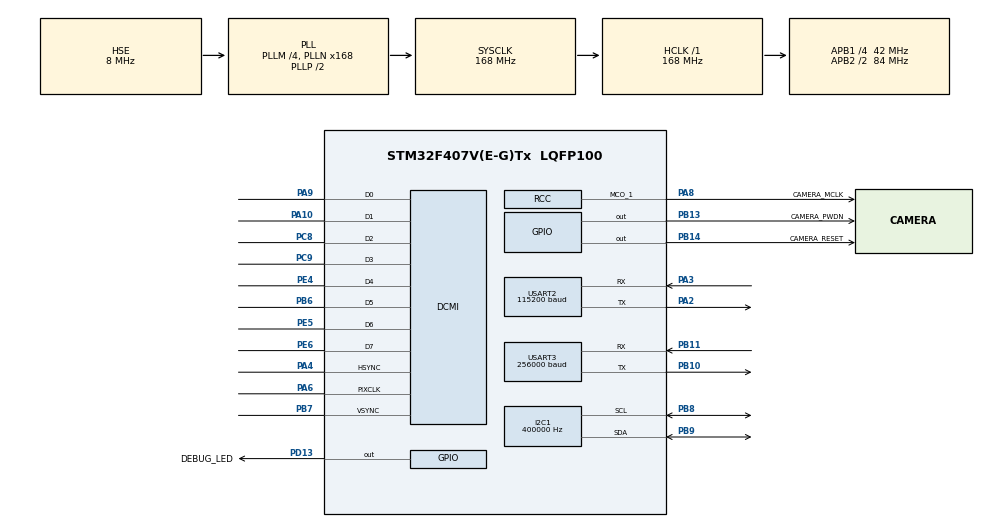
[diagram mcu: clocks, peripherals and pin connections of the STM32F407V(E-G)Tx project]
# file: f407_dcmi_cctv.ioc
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DCMI.JPEGMode=DCMI_JPEG_ENABLE
DCMI.PCKPolarity=DCMI_PCKPOLARITY_RISING
Dma.DCMI.0.Direction=DMA_PERIPH_TO_MEMORY
Dma.DCMI.0.FIFOMode=DMA_FIFOMODE_ENABLE
Dma.DCMI.0.FIFOThreshold=DMA_FIFO_THRESHOLD_FULL
Dma.DCMI.0.Instance=DMA2_Stream1
Dma.DCMI.0.MemBurst=DMA_MBURST_SINGLE
Dma.DCMI.0.MemDataAlignment=DMA_MDATAALIGN_WORD
Dma.DCMI.0.MemInc=DMA_MINC_ENABLE
Dma.DCMI.0.Mode=DMA_CIRCULAR
Dma.DCMI.0.PeriphBurst=DMA_PBURST_SINGLE
Dma.DCMI.0.PeriphDataAlignment=DMA_PDATAALIGN_WORD
Dma.DCMI.0.PeriphInc=DMA_PINC_DISABLE
Dma.DCMI.0.Priority=DMA_PRIORITY_VERY_HIGH
Dma.Request0=DCMI
Dma.Request1=USART3_TX
Dma.USART3_TX.1.Direction=DMA_MEMORY_TO_PERIPH
Dma.USART3_TX.1.FIFOMode=DMA_FIFOMODE_ENABLE
Dma.USART3_TX.1.FIFOThreshold=DMA_FIFO_THRESHOLD_FULL
Dma.USART3_TX.1.Instance=DMA1_Stream3
Dma.USART3_TX.1.MemBurst=DMA_MBURST_SINGLE
Dma.USART3_TX.1.MemDataAlignment=DMA_MDATAALIGN_BYTE
Dma.USART3_TX.1.MemInc=DMA_MINC_ENABLE
Dma.USART3_TX.1.Mode=DMA_CIRCULAR
Dma.USART3_TX.1.PeriphBurst=DMA_PBURST_SINGLE
Dma.USART3_TX.1.PeriphDataAlignment=DMA_PDATAALIGN_BYTE
Dma.USART3_TX.1.PeriphInc=DMA_PINC_DISABLE
Dma.USART3_TX.1.Priority=DMA_PRIORITY_VERY_HIGH
FREERTOS.Tasks01=wifiControl,0,128,StartWifiTask,Default,NULL,Dynamic,NULL,NULL;dcmiControl,-3,128,StartDCMITask,Default,NULL,Dynamic,NULL,NULL
I2C1.ClockSpeed=400000
I2C1.I2C_Mode=I2C_Fast
I2C1.NoStretchMode=I2C_NOSTRETCH_DISABLE
Mcu.Family=STM32F4
Mcu.Name=STM32F407V(E-G)Tx
Mcu.Package=LQFP100
NVIC.DCMI_IRQn=true\:5\:0\:false\:true\:true\:1\:true\:true\:true
NVIC.DMA1_Stream3_IRQn=true\:5\:0\:false\:false\:true\:true\:false\:true
NVIC.DMA2_Stream1_IRQn=true\:5\:0\:false\:false\:true\:true\:false\:true
NVIC.PriorityGroup=NVIC_PRIORITYGROUP_4
NVIC.TIM7_IRQn=true\:0\:0\:false\:false\:true\:false\:false\:true
NVIC.TimeBase=TIM7_IRQn
NVIC.TimeBaseIP=TIM7
NVIC.USART3_IRQn=true\:5\:0\:false\:true\:true\:2\:true\:true\:true
PA10.Mode=Slave_8_bits_External_Synchro
PA10.Signal=DCMI_D1
PA2.Mode=Asynchronous
PA2.Signal=USART2_TX
PA3.Mode=Asynchronous
PA3.Signal=USART2_RX
PA4.Mode=Slave_8_bits_External_Synchro
PA4.Signal=DCMI_HSYNC
PA6.Mode=Slave_8_bits_External_Synchro
PA6.Signal=DCMI_PIXCLK
PA8.GPIO_Label=CAMERA_MCLK
PA8.Mode=Clock-out-1
PA8.Signal=RCC_MCO_1
PA9.Mode=Slave_8_bits_External_Synchro
PA9.Signal=DCMI_D0
PB10.Mode=Asynchronous
PB10.Signal=USART3_TX
PB11.Mode=Asynchronous
PB11.Signal=USART3_RX
PB13.GPIO_Label=CAMERA_PWDN
PB13.Signal=GPIO_Output
PB14.GPIO_Label=CAMERA_RESET
PB14.Signal=GPIO_Output
PB6.Mode=Slave_8_bits_External_Synchro
PB6.Signal=DCMI_D5
PB7.Mode=Slave_8_bits_External_Synchro
PB7.Signal=DCMI_VSYNC
PB8.Mode=I2C
PB8.Signal=I2C1_SCL
PB9.Mode=I2C
PB9.Signal=I2C1_SDA
PC8.Mode=Slave_8_bits_External_Synchro
PC8.Signal=DCMI_D2
PC9.Mode=Slave_8_bits_External_Synchro
PC9.Signal=DCMI_D3
PD13.GPIO_Label=DEBUG_LED
PD13.Signal=GPIO_Output
PE4.Mode=Slave_8_bits_External_Synchro
PE4.Signal=DCMI_D4
PE5.Mode=Slave_8_bits_External_Synchro
PE5.Signal=DCMI_D6
PE6.Mode=Slave_8_bits_External_Synchro
PE6.Signal=DCMI_D7
PH0-OSC_IN.Mode=HSE-External-Oscillator
PH0-OSC_IN.Signal=RCC_OSC_IN
PH1-OSC_OUT.Mode=HSE-External-Oscillator
PH1-OSC_OUT.Signal=RCC_OSC_OUT
ProjectManager.HeapSize=0x200
ProjectManager.StackSize=0x400
ProjectManager.TargetToolchain=MDK-ARM V5.27
RCC.48MHZClocksFreq_Value=84000000
RCC.AHBFreq_Value=168000000
RCC.APB1CLKDivider=RCC_HCLK_DIV4
RCC.APB1Freq_Value=42000000
RCC.APB1TimFreq_Value=84000000
RCC.APB2CLKDivider=RCC_HCLK_DIV2
RCC.APB2Freq_Value=84000000
RCC.APB2TimFreq_Value=168000000
RCC.CortexFreq_Value=168000000
RCC.HCLKFreq_Value=168000000
RCC.HSE_VALUE=8000000
RCC.HSI_VALUE=16000000
RCC.PLLM=4
RCC.PLLN=168
RCC.PLLSourceVirtual=RCC_PLLSOURCE_HSE
RCC.RCC_MCO1Source=RCC_MCO1SOURCE_PLLCLK
RCC.RCC_MCODiv1=RCC_MCODIV_4
RCC.SYSCLKFreq_VALUE=168000000
RCC.SYSCLKSource=RCC_SYSCLKSOURCE_PLLCLK
RCC.VCOOutputFreq_Value=336000000
USART2.BaudRate=115200
USART2.VirtualMode=VM_ASYNC
USART3.BaudRate=256000
USART3.VirtualMode=VM_ASYNC
VP_FREERTOS_VS_CMSIS_V1.Mode=CMSIS_V1
VP_SYS_VS_tim7.Mode=TIM7
board=custom

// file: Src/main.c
/* USER CODE BEGIN Header */
/**
  ******************************************************************************
  * @file           : main.c
  * @brief          : Main program body
  ******************************************************************************
  * @attention
  *
  * <h2><center>&copy; Copyright (c) 2021 STMicroelectronics.
  * All rights reserved.</center></h2>
  *
  * This software component is licensed by ST under BSD 3-Clause license,
  * the "License"; You may not use this file except in compliance with the
  * License. You may obtain a copy of the License at:
  *                        opensource.org/licenses/BSD-3-Clause
  *
  ******************************************************************************
  */
/* USER CODE END Header */

#include "main.h"
#include "cmsis_os.h"
#include "dcmi.h"
#include "dma.h"
#include "i2c.h"
#include "usart.h"
#include "gpio.h"

/* USER CODE BEGIN Includes */
#include "Wifi.h"
#include <stdio.h>

/* USER CODE END Includes */

void SystemClock_Config(void);
void MX_FREERTOS_Init(void);
static void MX_NVIC_Init(void);

int main(void)
{

  /* MCU Configuration--------------------------------------------------------*/

  /* Reset of all peripherals, Initializes the Flash interface and the Systick. */
  HAL_Init();

  /* Configure the system clock */
  SystemClock_Config();

  /* Initialize all configured peripherals */
  MX_GPIO_Init();
  MX_DMA_Init();
  MX_USART3_UART_Init();
  MX_DCMI_Init();
  MX_I2C1_Init();
  MX_USART2_UART_Init();

  /* Initialize interrupts */
  MX_NVIC_Init();

  /* Call init function for freertos objects (in freertos.c) */
  MX_FREERTOS_Init();
  /* Start scheduler */
  osKernelStart();

  /* We should never get here as control is now taken by the scheduler */
  /* Infinite loop */
  while (1)
  {

  }
}

void SystemClock_Config(void)
{
  RCC_OscInitTypeDef RCC_OscInitStruct = {0};
  RCC_ClkInitTypeDef RCC_ClkInitStruct = {0};

  /** Configure the main internal regulator output voltage
  */
  __HAL_RCC_PWR_CLK_ENABLE();
  __HAL_PWR_VOLTAGESCALING_CONFIG(PWR_REGULATOR_VOLTAGE_SCALE1);
  /** Initializes the CPU, AHB and APB busses clocks
  */
  RCC_OscInitStruct.OscillatorType = RCC_OSCILLATORTYPE_HSE;
  RCC_OscInitStruct.HSEState = RCC_HSE_ON;
  RCC_OscInitStruct.PLL.PLLState = RCC_PLL_ON;
  RCC_OscInitStruct.PLL.PLLSource = RCC_PLLSOURCE_HSE;
  RCC_OscInitStruct.PLL.PLLM = 4;
  RCC_OscInitStruct.PLL.PLLN = 168;
  RCC_OscInitStruct.PLL.PLLP = RCC_PLLP_DIV2;
  RCC_OscInitStruct.PLL.PLLQ = 4;
  if (HAL_RCC_OscConfig(&RCC_OscInitStruct) != HAL_OK)
  {
    Error_Handler();
  }
  /** Initializes the CPU, AHB and APB busses clocks
  */
  RCC_ClkInitStruct.ClockType = RCC_CLOCKTYPE_HCLK|RCC_CLOCKTYPE_SYSCLK
                              |RCC_CLOCKTYPE_PCLK1|RCC_CLOCKTYPE_PCLK2;
  RCC_ClkInitStruct.SYSCLKSource = RCC_SYSCLKSOURCE_PLLCLK;
  RCC_ClkInitStruct.AHBCLKDivider = RCC_SYSCLK_DIV1;
  RCC_ClkInitStruct.APB1CLKDivider = RCC_HCLK_DIV4;
  RCC_ClkInitStruct.APB2CLKDivider = RCC_HCLK_DIV2;

  if (HAL_RCC_ClockConfig(&RCC_ClkInitStruct, FLASH_LATENCY_5) != HAL_OK)
  {
    Error_Handler();
  }
  HAL_RCC_MCOConfig(RCC_MCO1, RCC_MCO1SOURCE_PLLCLK, RCC_MCODIV_4);
}

/**
  * @brief NVIC Configuration.
  * @retval None
  */
static void MX_NVIC_Init(void)
{
  /* DCMI_IRQn interrupt configuration */
  HAL_NVIC_SetPriority(DCMI_IRQn, 5, 0);
  HAL_NVIC_EnableIRQ(DCMI_IRQn);
  /* USART3_IRQn interrupt configuration */
  HAL_NVIC_SetPriority(USART3_IRQn, 5, 0);
  HAL_NVIC_EnableIRQ(USART3_IRQn);
}

 /**
  * @brief  Period elapsed callback in non blocking mode
  * @note   This function is called  when TIM7 interrupt took place, inside
  * HAL_TIM_IRQHandler(). It makes a direct call to HAL_IncTick() to increment
  * a global variable "uwTick" used as application time base.
  * @param  htim : TIM handle
  * @retval None
  */
void HAL_TIM_PeriodElapsedCallback(TIM_HandleTypeDef *htim)
{
  if (htim->Instance == TIM7) {
    HAL_IncTick();
  }
}

void Error_Handler(void)
{
}

/************************ (C) COPYRIGHT STMicroelectronics *****END OF FILE****/

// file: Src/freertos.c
/* USER CODE BEGIN Header */
/**
  ******************************************************************************
  * File Name          : freertos.c
  * Description        : Code for freertos applications
  ******************************************************************************
  * @attention
  *
  * <h2><center>&copy; Copyright (c) 2021 STMicroelectronics.
  * All rights reserved.</center></h2>
  *
  * This software component is licensed by ST under Ultimate Liberty license
  * SLA0044, the "License"; You may not use this file except in compliance with
  * the License. You may obtain a copy of the License at:
  *                             www.st.com/SLA0044
  *
  ******************************************************************************
  */
/* USER CODE END Header */

#include "FreeRTOS.h"
#include "task.h"
#include "main.h"
#include "cmsis_os.h"

/* USER CODE BEGIN Includes */
#include <stdio.h>
#include "Wifi.h"
#include "camera_ctrl.h"
#include "usart.h"

/* USER CODE END Includes */

osThreadId wifiControlHandle;
osThreadId dcmiControlHandle;

void StartWifiTask(void const * argument);
void StartDCMITask(void const * argument);

void MX_FREERTOS_Init(void); /* (MISRA C 2004 rule 8.1) */

/* GetIdleTaskMemory prototype (linked to static allocation support) */
void vApplicationGetIdleTaskMemory( StaticTask_t **ppxIdleTaskTCBBuffer, StackType_t **ppxIdleTaskStackBuffer, uint32_t *pulIdleTaskStackSize );

/* USER CODE BEGIN GET_IDLE_TASK_MEMORY */
static StaticTask_t xIdleTaskTCBBuffer;
static StackType_t xIdleStack[configMINIMAL_STACK_SIZE];

void vApplicationGetIdleTaskMemory( StaticTask_t **ppxIdleTaskTCBBuffer, StackType_t **ppxIdleTaskStackBuffer, uint32_t *pulIdleTaskStackSize )
{
  *ppxIdleTaskTCBBuffer = &xIdleTaskTCBBuffer;
  *ppxIdleTaskStackBuffer = &xIdleStack[0];
  *pulIdleTaskStackSize = configMINIMAL_STACK_SIZE;
  /* place for user code */
}
/* USER CODE END GET_IDLE_TASK_MEMORY */

void MX_FREERTOS_Init(void) {

  /* Create the thread(s) */
  /* definition and creation of wifiControl */
  osThreadDef(wifiControl, StartWifiTask, osPriorityNormal, 0, 128);
  wifiControlHandle = osThreadCreate(osThread(wifiControl), NULL);

  /* definition and creation of dcmiControl */
  osThreadDef(dcmiControl, StartDCMITask, osPriorityIdle, 0, 128);
  dcmiControlHandle = osThreadCreate(osThread(dcmiControl), NULL);

}

void StartWifiTask(void const * argument)
{
  /* USER CODE BEGIN StartWifiTask */
	//Wifi_Init(osPriorityNormal);
  /* Infinite loop */
  for(;;)
  {
    osDelay(1);
  }
  /* USER CODE END StartWifiTask */
}

void StartDCMITask(void const * argument)
{
  /* USER CODE BEGIN StartDCMITask */
	printf("\r\n");
	Camera_UserProcess();
  /* Infinite loop */
  for(;;)
  {
//		HAL_GPIO_TogglePin(DEBUG_LED_GPIO_Port, DEBUG_LED_Pin);
		osDelay(1);
  }
  /* USER CODE END StartDCMITask */
}

/* USER CODE BEGIN Application */
void HAL_UART_RxCpltCallback(UART_HandleTypeDef *huart) {
	if(huart->Instance == USART3)	{
//		Wifi_RxCallBack();
	}
}

/* USER CODE END Application */

/************************ (C) COPYRIGHT STMicroelectronics *****END OF FILE****/
